# UART1 register map
Registers from a debugger description file.
Registers are 32-bit, access not given, no defined reset value unless marked. A register's access mark holds for its fields unless they carry their own. Addresses are absolute; registers are grouped by the start of their names; lines under a group give offsets from that group; [hi:lo] are bit positions; {n}, {i} and the like mark numbered series; 'fields as' and 'values as' point back to an identical list; <NAME> marks a mode.

## UART1
0x40060000 UART1/THR
  [7:0] THR
0x40060000 UART1/DLL
  [7:0] DLL
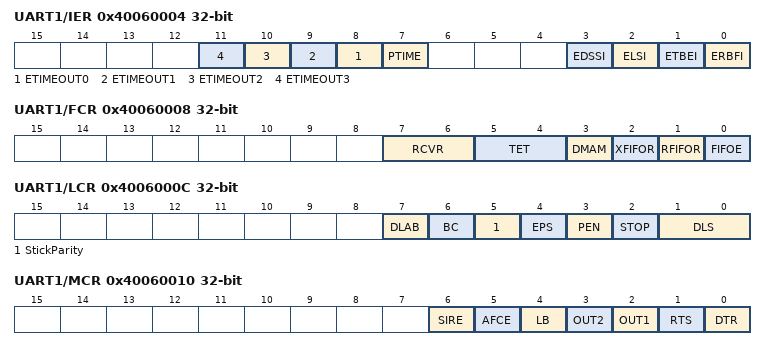
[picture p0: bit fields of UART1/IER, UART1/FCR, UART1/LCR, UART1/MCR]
0x40060004 UART1/IER
  [n+8] ETIMEOUT{n} (n=0..3), [7] PTIME, [3] EDSSI, [2] ELSI, [1] ETBEI, [0] ERBFI
0x40060004 UART1/DLH
  [7:0] DLH
0x40060008 UART1/FCR
  [7:6] RCVR, [5:4] TET, [3] DMAM, [2] XFIFOR, [1] RFIFOR, [0] FIFOE
0x4006000C UART1/LCR
  [7] DLAB, [6] BC, [5] StickParity, [4] EPS, [3] PEN, [2] STOP, [1:0] DLS
0x40060010 UART1/MCR
  [6] SIRE, [5] AFCE, [4] LB, [3] OUT2, [2] OUT1, [1] RTS, [0] DTR
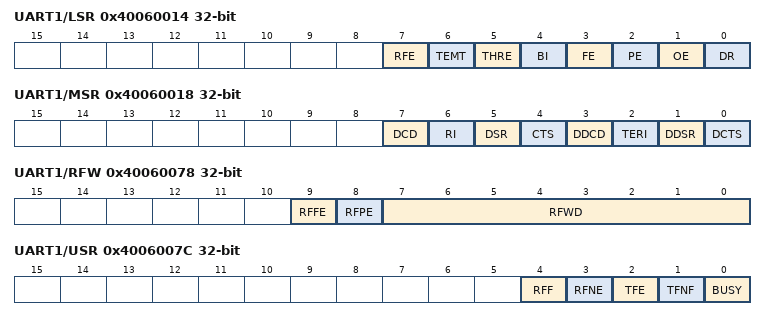
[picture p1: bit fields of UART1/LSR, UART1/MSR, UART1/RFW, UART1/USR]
0x40060014 UART1/LSR ro
  [7] RFE, [6] TEMT, [5] THRE, [4] BI, [3] FE, [2] PE, [1] OE, [0] DR
0x40060018 UART1/MSR ro
  [7] DCD, [6] RI, [5] DSR, [4] CTS, [3] DDCD, [2] TERI, [1] DDSR, [0] DCTS
0x4006001C UART1/SCR
  [7:0] SCR
0x40060030 UART1/STHR
  [7:0] STHR
0x40060070 UART1/FAR
  [0] FAR
0x40060074 UART1/TFR ro
  [7:0] TFR
0x40060078 UART1/RFW
  [9] RFFE, [8] RFPE, [7:0] RFWD
0x4006007C UART1/USR ro
  [4] RFF, [3] RFNE, [2] TFE, [1] TFNF, [0] BUSY
0x40060080 UART1/TFL ro
  [4:0] TFL
0x40060084 UART1/RFL ro
  [4:0] RFL
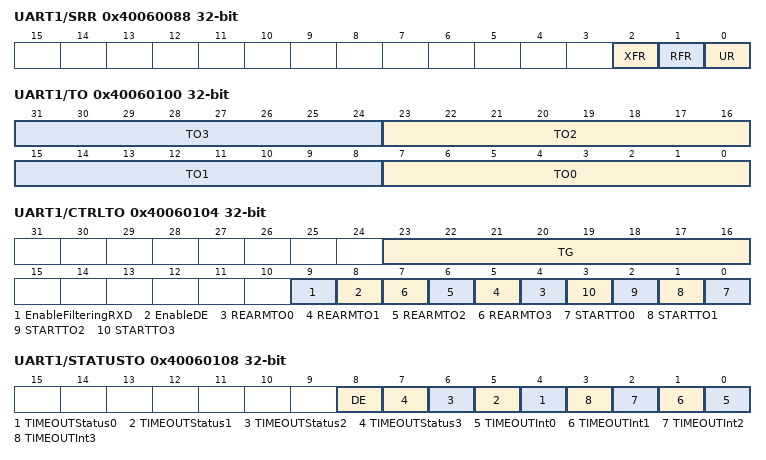
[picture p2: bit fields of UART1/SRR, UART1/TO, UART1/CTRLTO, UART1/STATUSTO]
0x40060088 UART1/SRR
  [2] XFR, [1] RFR, [0] UR
0x4006008C UART1/SRTS
  [0] SRTS
0x40060090 UART1/SBCR
  [0] SBCR
0x40060098 UART1/SFE
  [0] SFE
0x4006009C UART1/SRT
  [1:0] SRCVR
0x400600A0 UART1/STET
  [1:0] STET
0x400600A4 UART1/HTX
  [0] HTX
0x400600F8 UART1/UCV ro
  [31:0] Version
0x400600FC UART1/CTR ro
  [31:0] ID
0x40060100 UART1/TO
  [8n+7:8n] TO{n} (n=0..3)
0x40060104 UART1/CTRLTO
  [23:16] TG, [9] EnableFilteringRXD, [8] EnableDE, [n+4] REARMTO{n} (n=0..3), [n] STARTTO{n} (n=0..3)
0x40060108 UART1/STATUSTO
  [8] DE, [n+4] TIMEOUTStatus{n} (n=0..3), [n] TIMEOUTInt{n} (n=0..3)
